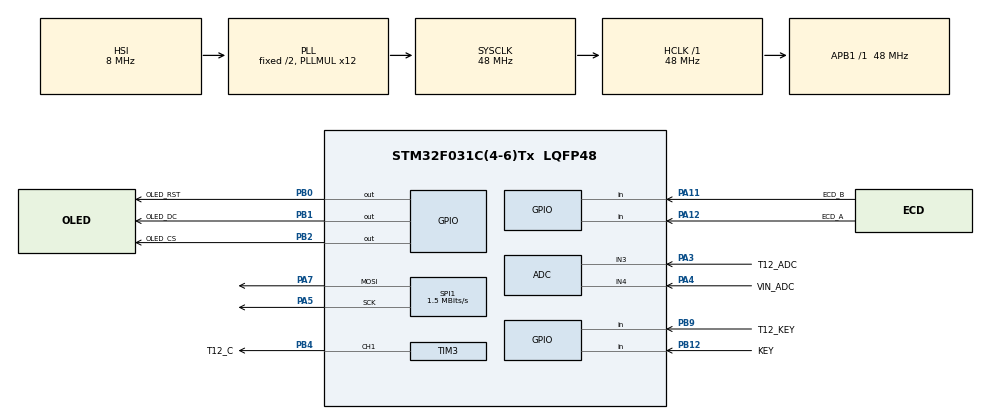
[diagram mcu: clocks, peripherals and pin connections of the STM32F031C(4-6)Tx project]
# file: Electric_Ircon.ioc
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ADC.ContinuousConvMode=ENABLE
ADC.DMAContinuousRequests=DISABLE
ADC.SamplingTime=ADC_SAMPLETIME_239CYCLES_5
Mcu.Family=STM32F0
Mcu.Name=STM32F031C(4-6)Tx
Mcu.Package=LQFP48
NVIC.TIM2_IRQn=true\:0\:0\:false\:false\:true\:true\:true
PA11.GPIO_Label=ECD_B
PA11.GPIO_PuPd=GPIO_PULLUP
PA11.Signal=GPIO_Input
PA12.GPIO_Label=ECD_A
PA12.GPIO_PuPd=GPIO_PULLUP
PA12.Signal=GPIO_Input
PA13.Mode=Serial_Wire
PA13.Signal=SYS_SWDIO
PA14.Mode=Serial_Wire
PA14.Signal=SYS_SWCLK
PA3.GPIO_Label=T12_ADC
PA3.Mode=IN3
PA3.Signal=ADC_IN3
PA4.GPIO_Label=VIN_ADC
PA4.Mode=IN4
PA4.Signal=ADC_IN4
PA5.GPIO_Speed=GPIO_SPEED_FREQ_LOW
PA5.Mode=TX_Only_Simplex_Unidirect_Master
PA5.Signal=SPI1_SCK
PA7.GPIO_Speed=GPIO_SPEED_FREQ_LOW
PA7.Mode=TX_Only_Simplex_Unidirect_Master
PA7.Signal=SPI1_MOSI
PB0.GPIO_Label=OLED_RST
PB0.GPIO_ModeDefaultOutputPP=GPIO_MODE_OUTPUT_PP
PB0.GPIO_Speed=GPIO_SPEED_FREQ_HIGH
PB0.PinState=GPIO_PIN_RESET
PB0.Signal=GPIO_Output
PB1.GPIO_Label=OLED_DC
PB1.GPIO_Speed=GPIO_SPEED_FREQ_HIGH
PB1.Signal=GPIO_Output
PB12.GPIO_Label=KEY
PB12.GPIO_PuPd=GPIO_PULLUP
PB12.Signal=GPIO_Input
PB2.GPIO_Label=OLED_CS
PB2.GPIO_Speed=GPIO_SPEED_FREQ_HIGH
PB2.Signal=GPIO_Output
PB4.GPIO_Label=T12_C
PB4.Signal=S_TIM3_CH1
PB9.GPIO_Label=T12_KEY
PB9.GPIO_PuPd=GPIO_PULLUP
PB9.Signal=GPIO_Input
ProjectManager.HeapSize=0x300
ProjectManager.StackSize=0x400
ProjectManager.TargetToolchain=MDK-ARM V5.27
RCC.AHBFreq_Value=48000000
RCC.APB1Freq_Value=48000000
RCC.APB1TimFreq_Value=48000000
RCC.HCLKFreq_Value=48000000
RCC.PLLMUL=RCC_PLL_MUL12
RCC.SYSCLKFreq_VALUE=48000000
RCC.SYSCLKSource=RCC_SYSCLKSOURCE_PLLCLK
SH.S_TIM3_CH1.0=TIM3_CH1,PWM Generation1 CH1
SPI1.BaudRatePrescaler=SPI_BAUDRATEPRESCALER_32
SPI1.CalculateBaudRate=1.5 MBits/s
SPI1.DataSize=SPI_DATASIZE_8BIT
SPI1.Direction=SPI_DIRECTION_2LINES
SPI1.FirstBit=SPI_FIRSTBIT_MSB
SPI1.Mode=SPI_MODE_MASTER
SPI1.VirtualType=VM_MASTER
TIM2.AutoReloadPreload=TIM_AUTORELOAD_PRELOAD_ENABLE
TIM2.Period=100
TIM2.Prescaler=47
TIM3.AutoReloadPreload=TIM_AUTORELOAD_PRELOAD_ENABLE
TIM3.Channel-PWM\ Generation1\ CH1=TIM_CHANNEL_1
TIM3.OCPolarity_1=TIM_OCPOLARITY_HIGH
TIM3.Period=99
TIM3.Prescaler=4799
VP_TIM2_VS_ClockSourceINT.Mode=Internal
VP_TIM3_VS_ClockSourceINT.Mode=Internal
board=custom

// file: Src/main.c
/* USER CODE BEGIN Header */
/**
  ******************************************************************************
  * @file           : main.c
  * @brief          : Main program body
  ******************************************************************************
  * @attention
  *
  * <h2><center>&copy; Copyright (c) 2022 STMicroelectronics.
  * All rights reserved.</center></h2>
  *
  * This software component is licensed by ST under BSD 3-Clause license,
  * the "License"; You may not use this file except in compliance with the
  * License. You may obtain a copy of the License at:
  *                        opensource.org/licenses/BSD-3-Clause
  *
  ******************************************************************************
  */
/* USER CODE END Header */

#include "main.h"
#include "adc.h"
#include "spi.h"
#include "tim.h"
#include "gpio.h"

/* USER CODE BEGIN Includes */
#include "ctrl.h"
/* USER CODE END Includes */

void SystemClock_Config(void);

int main(void)
{

  /* MCU Configuration--------------------------------------------------------*/

  /* Reset of all peripherals, Initializes the Flash interface and the Systick. */
  HAL_Init();

  /* Configure the system clock */
  SystemClock_Config();

  /* Initialize all configured peripherals */
  MX_GPIO_Init();
  MX_ADC_Init();
  MX_SPI1_Init();
  MX_TIM2_Init();
  MX_TIM3_Init();
  /* USER CODE BEGIN 2 */
  HAL_TIM_Base_Start_IT(&htim3);
  HAL_TIM_Base_Start_IT(&htim2);
  // HAL_TIM_PWM_Start_IT(&htim1, TIM_CHANNEL_4);
  HAL_TIM_PWM_Start(&htim3, TIM_CHANNEL_1);
  /* USER CODE END 2 */

  /* Infinite loop */
  /* USER CODE BEGIN WHILE */
  // while (1)
  // {
    /* USER CODE END WHILE */

    /* USER CODE BEGIN 3 */
  // }
    ctrl_main();
  /* USER CODE END 3 */
}

void SystemClock_Config(void)
{
  RCC_OscInitTypeDef RCC_OscInitStruct = {0};
  RCC_ClkInitTypeDef RCC_ClkInitStruct = {0};

  /** Initializes the CPU, AHB and APB busses clocks
  */
  RCC_OscInitStruct.OscillatorType = RCC_OSCILLATORTYPE_HSI|RCC_OSCILLATORTYPE_HSI14;
  RCC_OscInitStruct.HSIState = RCC_HSI_ON;
  RCC_OscInitStruct.HSI14State = RCC_HSI14_ON;
  RCC_OscInitStruct.HSICalibrationValue = RCC_HSICALIBRATION_DEFAULT;
  RCC_OscInitStruct.HSI14CalibrationValue = 16;
  RCC_OscInitStruct.PLL.PLLState = RCC_PLL_ON;
  RCC_OscInitStruct.PLL.PLLSource = RCC_PLLSOURCE_HSI;
  RCC_OscInitStruct.PLL.PLLMUL = RCC_PLL_MUL12;
  RCC_OscInitStruct.PLL.PREDIV = RCC_PREDIV_DIV1;
  if (HAL_RCC_OscConfig(&RCC_OscInitStruct) != HAL_OK)
  {
    Error_Handler();
  }
  /** Initializes the CPU, AHB and APB busses clocks
  */
  RCC_ClkInitStruct.ClockType = RCC_CLOCKTYPE_HCLK|RCC_CLOCKTYPE_SYSCLK
                              |RCC_CLOCKTYPE_PCLK1;
  RCC_ClkInitStruct.SYSCLKSource = RCC_SYSCLKSOURCE_PLLCLK;
  RCC_ClkInitStruct.AHBCLKDivider = RCC_SYSCLK_DIV1;
  RCC_ClkInitStruct.APB1CLKDivider = RCC_HCLK_DIV1;

  if (HAL_RCC_ClockConfig(&RCC_ClkInitStruct, FLASH_LATENCY_1) != HAL_OK)
  {
    Error_Handler();
  }
}

void Error_Handler(void)
{
  /* USER CODE BEGIN Error_Handler_Debug */
  /* User can add his own implementation to report the HAL error return state */
  RTT_LOG_DEBUG("Error_Handler\r\n");
  /* USER CODE END Error_Handler_Debug */
}

/************************ (C) COPYRIGHT STMicroelectronics *****END OF FILE****/
